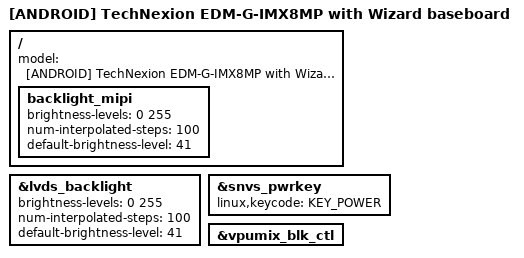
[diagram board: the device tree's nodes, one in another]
// SPDX-License-Identifier: (GPL-2.0+ OR MIT)
/*
 * Copyright 2020 Technexion Ltd.
 *
 * Author: Richard Hu <richard.hu@technexion.com>
 *
 */

/dts-v1/;

#include "imx8mp-edm-g-wizard.dts"
#include "imx8mp-android.dtsi"

/ {
	model = "[ANDROID] TechNexion EDM-G-IMX8MP with Wizard baseboard";

	backlight_mipi {
		brightness-levels = <0 255>;
		num-interpolated-steps = <100>;
		default-brightness-level = <41>;
	};
};

&lvds_backlight {
	brightness-levels = <0 255>;
	num-interpolated-steps = <100>;
	default-brightness-level = <41>;
};

&snvs_pwrkey {
	linux,keycode = <KEY_POWER>;
};

&vpumix_blk_ctl {
	/delete-property/ trusty;
};
